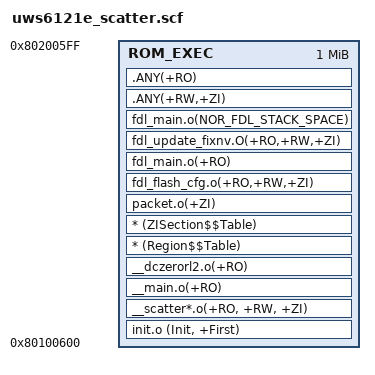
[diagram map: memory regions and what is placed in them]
ROM_LOAD 0x80100600 0x100000
{  
   ROM_EXEC 0x80100600 0x100000
   {
        init.o (Init, +First)
        __scatter*.o(+RO, +RW, +ZI)
        __main.o(+RO)
        __dczerorl2.o(+RO)
        * (Region$$Table)
        * (ZISection$$Table)
        packet.o(+ZI) 
        fdl_flash_cfg.o(+RO,+RW,+ZI) 
        fdl_main.o(+RO)
        fdl_update_fixnv.O(+RO,+RW,+ZI) 
        fdl_main.o(NOR_FDL_STACK_SPACE)
        .ANY(+RW,+ZI)
        .ANY(+RO)
  }
}

